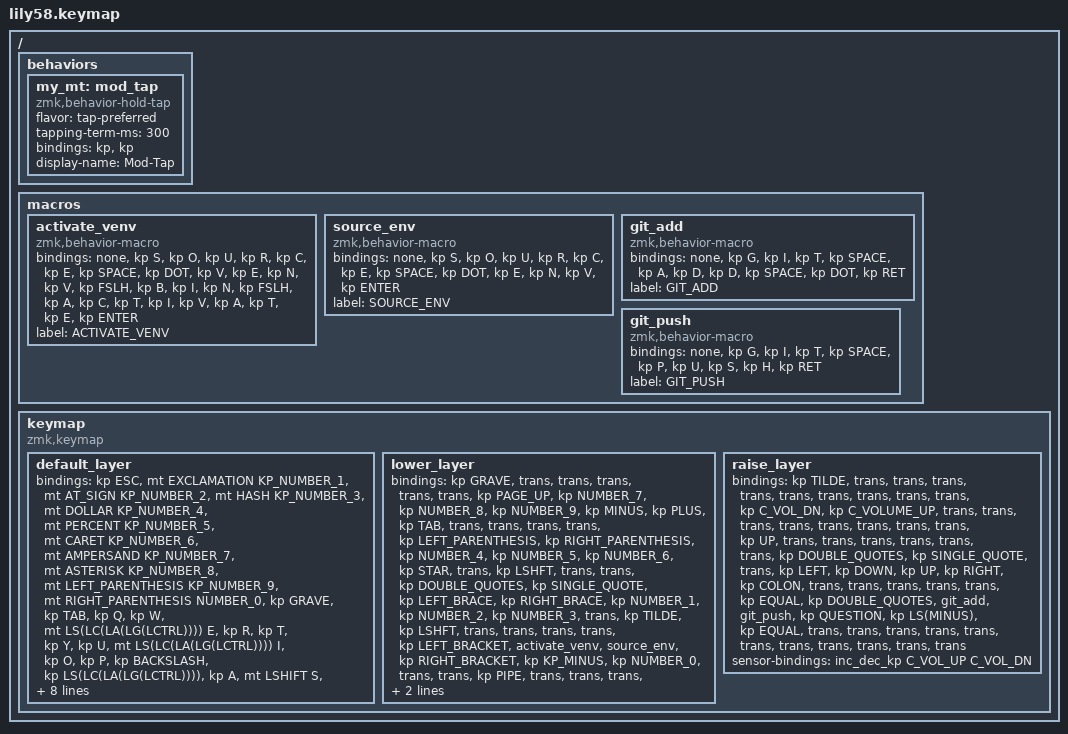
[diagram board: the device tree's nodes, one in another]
/*
 * Copyright (c) 2020 The ZMK Contributors
 *
 * SPDX-License-Identifier: MIT
 */

#include <behaviors.dtsi>
#include <dt-bindings/zmk/keys.h>
#include <dt-bindings/zmk/bt.h>
#include <dt-bindings/zmk/ext_power.h>


/ {
    behaviors {
        my_mt: mod_tap {
            compatible = "zmk,behavior-hold-tap";
            #binding-cells = <2>;
            flavor = "tap-preferred";
            tapping-term-ms = <300>;
            bindings = <&kp>, <&kp>;
            display-name = "Mod-Tap";
        };
    };
};


/ {
    macros {
        activate_venv: activate_venv {
            compatible = "zmk,behavior-macro";
            #binding-cells = <0>;
            bindings = <
                &none &kp S &kp O &kp U &kp R &kp C &kp E &kp SPACE
                &kp DOT &kp V &kp E &kp N &kp V &kp FSLH &kp B &kp I
                &kp N &kp FSLH &kp A &kp C &kp T &kp I &kp V &kp A
                &kp T &kp E &kp ENTER
            >;
            label = "ACTIVATE_VENV";
        };

        source_env: source_env {
            compatible = "zmk,behavior-macro";
            #binding-cells = <0>;
            bindings = <
                &none &kp S &kp O &kp U &kp R &kp C &kp E &kp SPACE
                &kp DOT &kp E &kp N &kp V &kp ENTER
            >;
            label = "SOURCE_ENV";
        };

        git_add: git_add {
            compatible = "zmk,behavior-macro";
            #binding-cells = <0>;
            bindings = <
                &none &kp G &kp I &kp T &kp SPACE &kp A &kp D &kp D
                &kp SPACE &kp DOT &kp RET
            >;
            label = "GIT_ADD";
        };

        git_push: git_push {
            compatible = "zmk,behavior-macro";
            #binding-cells = <0>;
            bindings = <
                &none &kp G &kp I &kp T &kp SPACE &kp P &kp U &kp S
                &kp H &kp RET
            >;
            label = "GIT_PUSH";
        };
    };


    keymap {
        compatible = "zmk,keymap";

        default_layer {
            // ------------------------------------------------------------------------------------------------------------
            // |  ESC  |  1  |  2  |  3   |  4   |  5   |                   |  6   |  7    |  8    |  9   |   0   |   `   |
            // |  TAB  |  Q  |  W  |  E   |  R   |  T   |                   |  Y   |  U    |  I    |  O   |   P   |   \\   |
            // | CTRL  |  A  |  S  |  D   |  F   |  G   |                   |  H   |  J    |  K    |  L   |   ;   |   '   |
            // | SHIFT |  Z  |  X  |  C   |  V   |  B   | "["   | "]"      |  N   |  M    |  ,    |  .   |   /   | SHIFT |
            //                     | ALT  | GUI  | LOWER| SPACE | ENTER| RAISE| BSPC | CAGS|

            bindings = <
                &kp ESC                     &mt EXCLAMATION KP_NUMBER_1   &mt AT_SIGN KP_NUMBER_2
                &mt HASH KP_NUMBER_3       &mt DOLLAR KP_NUMBER_4       &mt PERCENT KP_NUMBER_5
                &mt CARET KP_NUMBER_6      &mt AMPERSAND KP_NUMBER_7    &mt ASTERISK KP_NUMBER_8
                &mt LEFT_PARENTHESIS KP_NUMBER_9 &mt RIGHT_PARENTHESIS NUMBER_0 &kp GRAVE

                &kp TAB                                         &kp Q                        &kp W
                &mt LS(LC(LA(LG(LCTRL)))) E                     &kp R                        &kp T
                &kp Y                                           &kp U                        &mt LS(LC(LA(LG(LCTRL)))) I
                &kp O                                           &kp P                        &kp BACKSLASH

                &kp LS(LC(LA(LG(LCTRL))))  &kp A                        &mt LSHIFT S
                &kp D                      &kp F                        &kp G
                &kp H                      &kp J                        &kp K
                &mt RSHIFT L               &kp SEMICOLON                &kp SINGLE_QUOTE

                &kp LSHFT                   &mt LCTRL Z                  &kp X
                &mt LC(C) C                 &kp V                        &kp B
                &kp LBKT                    &kp RBKT                     &kp N
                &kp M                       &kp COMMA                    &kp DOT
                &kp FSLH                    &kp RSHFT

                &kp LALT                           &kp LGUI                      &mo 1
                &mt LSHIFT SPACE                   &mt LGUI RET                  &mo 2
                &kp BSPC                           &kp LCTRL
            >;

            sensor-bindings = <&inc_dec_kp C_VOL_UP C_VOL_DN>;
        };


        lower_layer {
            // ------------------------------------------------------------------------------------------------------------
            // |   `   |     |     |     |     |     |                   | PGUP |  7    |  8    |  9   |   -   |   +   |
            // |  TAB  |     |     |     |     |  (  |                   |  )   |  4    |  5    |  6   |   *   |       |
            // | SHIFT |     |     |  "  |  '  |  {  |                   |  }   |  1    |  2    |  3   |       |   ~   |
            // | SHIFT |     |     |     |     |  [  |                   |      |       |  ]    |  KP- |   0   |   |   |
            //                     |       |       |       |       |       |       |  BTCLR |

            bindings = <
                &kp GRAVE    &trans   &trans   &trans   &trans   &trans
                &kp PAGE_UP  &kp NUMBER_7 &kp NUMBER_8 &kp NUMBER_9 &kp MINUS &kp PLUS

                &kp TAB       &trans   &trans   &trans   &trans   &kp LEFT_PARENTHESIS
                &kp RIGHT_PARENTHESIS &kp NUMBER_4 &kp NUMBER_5 &kp NUMBER_6 &kp STAR &trans

                &kp LSHFT       &trans   &trans   &kp DOUBLE_QUOTES  &kp SINGLE_QUOTE   &kp LEFT_BRACE
                &kp RIGHT_BRACE    &kp NUMBER_1 &kp NUMBER_2 &kp NUMBER_3 &trans &kp TILDE

                &kp LSHFT       &trans   &trans   &trans   &trans   &kp LEFT_BRACKET
                &activate_venv &source_env &kp RIGHT_BRACKET &kp KP_MINUS &kp NUMBER_0 &trans &trans &kp PIPE

                &trans &trans &trans &trans &trans &trans &trans &trans &kp LG(LC(Q))
            >;
        };


        raise_layer {
            // ------------------------------------------------------------------------------------------------------------
            // |   ~   |     |     |     |     |     |                   |       |       |       |       | VOL_DN| VOL_UP|
            // |       |     |     |     |     |     |                   |       |       |       |       |       |       |
            // |       |     |     |  "  |  '  |     |                   |   :   |  <-   |   v   |   ^   |  ->   |       |
            // |       |     |     |     |   = |   " |                   |GIT_ADD|GIT_PSH|   ?   |   _   |   =   |       |
            //                     |       |       |       |       |       |       |       |

            bindings = <
                &kp TILDE    &trans   &trans   &trans   &trans   &trans
                &trans       &trans   &trans   &trans   &kp C_VOL_DN &kp C_VOLUME_UP

                &trans       &trans   &trans   &trans   &trans   &trans
                &trans       &trans   &kp UP &trans &trans &trans

                &trans       &trans   &trans   &kp DOUBLE_QUOTES  &kp SINGLE_QUOTE &trans
                &kp LEFT     &kp DOWN &kp UP   &kp RIGHT &kp COLON  &trans

                &trans       &trans   &trans   &trans   &kp EQUAL &kp DOUBLE_QUOTES
                &git_add     &git_push &kp QUESTION &kp LS(MINUS) &kp EQUAL &trans &trans &trans

                &trans &trans &trans &trans &trans &trans &trans &trans
            >;

            sensor-bindings = <&inc_dec_kp C_VOL_UP C_VOL_DN>;
        };
    };
};
